VERSION ""

NS_ :

BS_:

BU_: Tritium DriverControls

BO_ 3221225472 VECTOR__INDEPENDENT_SIG_MSG: 0 Vector__XXX
 SG_ Reserved2 : 32|32@1- (1,0) [0|0] "C" Vector__XXX

BO_ 768 IdentificationInfo: 8 Tritium
 SG_ TritiumId : 0|32@1+ (1,0) [0|0] "" Vector__XXX
 SG_ SerialNumber : 32|32@1+ (1,0) [0|0] "" Vector__XXX

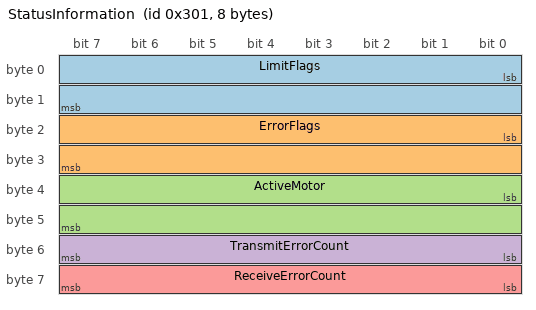
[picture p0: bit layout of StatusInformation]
BO_ 769 StatusInformation: 8 Tritium
 SG_ LimitFlags : 0|16@1+ (1,0) [0|0] "" Vector__XXX
 SG_ ErrorFlags : 16|16@1+ (1,0) [0|0] "" Vector__XXX
 SG_ ActiveMotor : 32|16@1+ (1,0) [0|0] "" Vector__XXX
 SG_ TransmitErrorCount : 48|8@1+ (1,0) [0|0] "" Vector__XXX
 SG_ ReceiveErrorCount : 56|8@1+ (1,0) [0|0] "" Vector__XXX

BO_ 770 BusMeasurement: 8 Tritium
 SG_ BusVoltage : 0|32@1- (1,0) [0|0] "V" Vector__XXX
 SG_ BusCurrent : 32|32@1- (1,0) [0|0] "A" Vector__XXX

BO_ 771 Velocity: 8 Tritium
 SG_ MotorVelocity : 0|32@1- (1,0) [0|0] "rpm" Vector__XXX
 SG_ VehicleVelocity : 32|32@1- (1,0) [0|0] "m/s" Vector__XXX

BO_ 772 PhaseCurrent: 8 Tritium
 SG_ PhaseBCurrent : 0|32@1- (1,0) [0|0] "A_rms" Vector__XXX
 SG_ PhaseCCurrent : 32|32@1- (1,0) [0|0] "A_rms" Vector__XXX

BO_ 773 MotorVoltageVector: 8 Tritium
 SG_ VectVoltImag : 0|32@1- (1,0) [0|0] "V" Vector__XXX
 SG_ VectVoltReal : 32|32@1- (1,0) [0|0] "V" Vector__XXX

BO_ 774 MotorCurrentVector: 8 Tritium
 SG_ VectCurrImag : 0|32@1- (1,0) [0|0] "A" Vector__XXX
 SG_ VectCurrReal : 32|32@1- (1,0) [0|0] "A" Vector__XXX

BO_ 775 MotorBackemfVector: 8 Tritium
 SG_ PeakBackEmfPhaseToNeutral : 0|32@1- (1,0) [0|0] "V" Vector__XXX
 SG_ BackEmfD : 32|32@1- (1,0) [0|0] "V" Vector__XXX

BO_ 776 Rail_15V: 8 Tritium
 SG_ Reserved : 0|32@1- (1,0) [0|0] "V" Vector__XXX
 SG_ FifteenVSupply : 32|32@1- (1,0) [0|0] "V" Vector__XXX

BO_ 777 Rail_3_3VAnd1_9V: 8 Tritium
 SG_ ThreeThreeVSupply : 32|32@1- (1,0) [0|0] "V" Vector__XXX
 SG_ OneNineVSupply : 0|32@1- (1,0) [0|0] "V" Vector__XXX

BO_ 778 Reserved1: 8 Tritium
 SG_ VoltagePercentage : 0|32@1- (1,0) [0|0] "%" Vector__XXX
 SG_ FanSpeed : 32|32@1- (1,0) [0|0] "rpm" Vector__XXX

BO_ 779 SinkMotorTemperature: 8 Tritium
 SG_ MotorTemp : 0|32@1- (1,0) [0|0] "C" Vector__XXX
 SG_ HeatSinkTemp : 32|32@1- (1,0) [0|0] "C" Vector__XXX

BO_ 780 DspBoardTemperature: 8 Tritium
 SG_ DspBoardTemp : 0|32@1- (1,0) [0|0] "C" Vector__XXX
 SG_ Reserved : 32|32@1- (1,0) [0|0] "C" Vector__XXX

BO_ 781 Reserved: 8 Tritium
 SG_ Reserved0 : 0|32@1- (1,0) [0|0] "" Vector__XXX
 SG_ Reserved : 32|32@1- (1,0) [0|0] "C" Vector__XXX

BO_ 782 OdoBusAmphours: 8 Tritium
 SG_ Odometer : 0|32@1- (1,0) [0|0] "m" Vector__XXX
 SG_ DcBusAmpHours : 32|32@1- (1,0) [0|0] "Ah" Vector__XXX

BO_ 791 SlipSpeedMeasurement: 8 Tritium
 SG_ Reserved : 0|32@1- (1,0) [0|0] "C" Vector__XXX
 SG_ SlipSpeed : 32|32@1- (1,0) [0|0] "Hz" Vector__XXX

BO_ 257 SpeedValCurrVal: 8 DriverControls
 SG_ DriverSetSpeed : 0|32@1- (1,0) [0|0] "rpm" Vector__XXX
 SG_ DriverSetCurrent : 32|32@1- (1,0) [0|1] "" Vector__XXX

BO_ 258 Maxbuscurrent: 8 DriverControls
 SG_ MaxBusCurrent : 32|32@1- (1,0) [0|1] "" Vector__XXX
 SG_ Zero : 0|32@1- (1,0) [0|0] "" Vector__XXX

BO_ 1280 DialCurrent: 8 DriverControls
 SG_ DriverSetDialCurrent : 0|32@1- (1,0) [0|1] "" Vector__XXX
 SG_ TotalAcMotorCurrent : 32|32@1- (1,0) [0|1] "" Vector__XXX

CM_ BU_ Tritium "Tritium WaveSculptor22 motor controller: drives the motor and reports its speed, currents, voltages and temperatures. Base address 0x300 (messages 0x300 to 0x317), as in Tests/data/NRT.BIN (iESC 2026 qualifying), where it reports device identifier 0x4003 (WaveSculptor22) and serial number 3315. The 2024 car's controller used base address 0x600. TODO: add the controller firmware version.";
CM_ BU_ DriverControls "Driver controls: send the driver's drive and power commands to the motor controller (base address 0x100), and the current dial setting (0x500).";
CM_ BO_ 3221225472 "Placeholder created by the Vector DBC editor to hold signals that are not in any message. Never sent on the bus.";
CM_ SG_ 3221225472 Reserved2 "Not used.";
CM_ BO_ 768 "Motor controller identification. Sent once a second.";
CM_ SG_ 768 TritiumId "Device identifier, fixed for the model (sent as the characters TRIa on some models).";
CM_ SG_ 768 SerialNumber "Device serial number, allocated at manufacture.";
CM_ BO_ 769 "Motor controller status: which limits are active, errors, and CAN error counts.";
CM_ SG_ 769 ActiveMotor "Index of the motor profile currently in use.";
CM_ SG_ 769 ErrorFlags "Error flags, one bit each (bit 0 hardware over current, bit 1 software over current, bit 2 DC bus over voltage, bit 3 bad motor position hall sequence, bit 4 watchdog caused the last reset, bit 5 config read error, bit 6 15 V rail under voltage lock out). 0 = no errors. TODO: add the remaining bits from the WaveSculptor22 user manual.";
CM_ SG_ 769 LimitFlags "Which limit is currently restricting the controller's output, one bit each (bit 0 bridge PWM, bit 1 motor current, bit 2 velocity, bit 3 bus current, bit 4 bus voltage upper limit, bit 5 bus voltage lower limit, bit 6 heatsink temperature).";
CM_ SG_ 769 TransmitErrorCount "Number of CAN transmit errors counted by the controller.";
CM_ SG_ 769 ReceiveErrorCount "Number of CAN receive errors counted by the controller.";
CM_ BO_ 770 "Battery-side (DC bus) voltage and current at the motor controller.";
CM_ SG_ 770 BusVoltage "DC bus (battery) voltage at the controller.";
CM_ SG_ 770 BusCurrent "Current drawn from the DC bus (battery) by the controller.";
CM_ BO_ 771 "Motor speed and vehicle speed.";
CM_ SG_ 771 MotorVelocity "Motor speed in revolutions per minute.";
CM_ SG_ 771 VehicleVelocity "Vehicle speed in metres per second, calculated by the controller from the motor speed and the wheel size set in its configuration.";
CM_ BO_ 772 "Current in two of the motor's three phases.";
CM_ SG_ 772 PhaseBCurrent "RMS current in motor phase B.";
CM_ SG_ 772 PhaseCCurrent "RMS current in motor phase C.";
CM_ BO_ 773 "Voltage applied to the motor, as a vector (mainly for motor tuning).";
CM_ SG_ 773 VectVoltImag "Imaginary component of the voltage vector applied to the motor.";
CM_ SG_ 773 VectVoltReal "Real component of the voltage vector applied to the motor.";
CM_ BO_ 774 "Current in the motor, as a vector (mainly for motor tuning).";
CM_ SG_ 774 VectCurrImag "Imaginary component of the motor current vector. This is the current that produces torque.";
CM_ SG_ 774 VectCurrReal "Real component of the motor current vector: the field current of the motor.";
CM_ BO_ 775 "Back-EMF (the voltage generated by the spinning motor), as a vector.";
CM_ SG_ 775 PeakBackEmfPhaseToNeutral "Peak phase to neutral back-EMF voltage of the motor.";
CM_ SG_ 775 BackEmfD "By definition always 0 V.";
CM_ BO_ 776 "Voltage of the controller's internal 15 V supply rail.";
CM_ SG_ 776 Reserved "Reserved, not used.";
CM_ SG_ 776 FifteenVSupply "Actual voltage of the internal 15 V supply rail.";
CM_ BO_ 777 "Voltages of the controller's internal 3.3 V and 1.9 V supply rails.";
CM_ SG_ 777 ThreeThreeVSupply "Actual voltage of the internal 3.3 V supply rail.";
CM_ SG_ 777 OneNineVSupply "Actual voltage of the internal 1.9 V (processor) supply rail.";
CM_ BO_ 778 "Cooling fan drive and speed (WaveSculptor20 layout). Marked reserved and not active in the 2023 CAN bus config spreadsheet (CANBusConfig.xlsm, removed in commit 210999e), and not seen in Tests/data/NRT.BIN. TODO: add whether Peri's motor controller sends this message; if not, remove it.";
CM_ SG_ 778 VoltagePercentage "Drive voltage to the cooling fan, in percent. Above 0 % the fan should be spinning.";
CM_ SG_ 778 FanSpeed "Cooling fan speed in revolutions per minute.";
CM_ BO_ 779 "Motor and controller heatsink temperatures.";
CM_ SG_ 779 MotorTemp "Internal temperature of the motor.";
CM_ SG_ 779 HeatSinkTemp "Surface temperature of the controller's heatsink.";
CM_ BO_ 780 "Temperature of the controller's processor board.";
CM_ SG_ 780 DspBoardTemp "Temperature of the controller's processor (DSP) board.";
CM_ SG_ 780 Reserved "Reserved, not used.";
CM_ BO_ 781 "Reserved message: marked reserved and not active in the 2023 CAN bus config spreadsheet (CANBusConfig.xlsm, removed in commit 210999e), but it does appear in Tests/data/NRT.BIN. TODO: add what Peri's motor controller sends in this message (base address + 0x0D), from the WaveSculptor22 user manual.";
CM_ SG_ 781 Reserved0 "Reserved, first half of the message (bits 0 to 31): see the message comment.";
CM_ SG_ 781 Reserved "Reserved, second half of the message (bits 32 to 63). TODO: add its meaning, see the message comment.";
CM_ BO_ 782 "Distance travelled and charge used since the controller was reset.";
CM_ SG_ 782 Odometer "Distance the vehicle has travelled since the controller was reset.";
CM_ SG_ 782 DcBusAmpHours "Charge drawn from the DC bus (battery) since the controller was reset.";
CM_ BO_ 791 "Slip speed (only meaningful with an induction motor).";
CM_ SG_ 791 Reserved "Reserved, not used.";
CM_ SG_ 791 SlipSpeed "Slip speed when driving an induction motor.";
CM_ BO_ 257 "Drive command from the driver controls to the motor controller: target speed and motor current.";
CM_ SG_ 257 DriverSetSpeed "Target motor speed requested by the driver controls, in motor rpm (negative = reverse). Evidence: the 16 BIN captures in (Aug to Nov 2026): about 480 rpm while the motor turns at about 330 rpm, i.e. set above the actual speed so that the current request (DriverSetCurrent) controls the car.";
CM_ SG_ 257 DriverSetCurrent "Motor current requested by the driver controls, as a fraction of the controller's maximum current setting (0 to 1, not 0 to 100). Evidence: the 16 BIN captures in (Aug to Nov 2026): 0 to 0.96.";
CM_ BO_ 258 "Power command from the driver controls: limit on the current drawn from the battery.";
CM_ SG_ 258 MaxBusCurrent "Limit on current drawn from the DC bus (battery), as a fraction of the controller's absolute bus current limit (0 to 1, not 0 to 100). Evidence: the 16 BIN captures in (Aug to Nov 2026): always 1.0.";
CM_ SG_ 258 Zero "Reserved, always 0.";
CM_ BO_ 1280 "Current dial setting from the driver controls (DriverSetCurrent in the ESC-CODE decode sheet). Seen in Tests/data/NRT.BIN.";
CM_ SG_ 1280 DriverSetDialCurrent "Setting of the driver's current dial, as a fraction (nominally 0 to 1). Evidence: the 16 BIN captures in (Aug to Nov 2026): 0 to 1.21. It is the upper limit for TotalAcMotorCurrent.";
CM_ SG_ 1280 TotalAcMotorCurrent "Motor current command sent to the motor controller, as a fraction (0 to 1). Evidence: the 16 BIN captures in (Aug to Nov 2026): 0 to 0.92, never above DriverSetDialCurrent, and in iESC2026_raceday1.BIN equal to the latest DriverSetCurrent in 87 % of messages.";
BA_DEF_ BO_  "GenMsgCycleTime" INT 0 65535;
BA_DEF_DEF_  "GenMsgCycleTime" 0;
BA_ "GenMsgCycleTime" BO_ 768 1000;
BA_ "GenMsgCycleTime" BO_ 769 200;
BA_ "GenMsgCycleTime" BO_ 770 200;
BA_ "GenMsgCycleTime" BO_ 771 200;
BA_ "GenMsgCycleTime" BO_ 772 200;
BA_ "GenMsgCycleTime" BO_ 773 200;
BA_ "GenMsgCycleTime" BO_ 774 200;
BA_ "GenMsgCycleTime" BO_ 775 200;
BA_ "GenMsgCycleTime" BO_ 776 1000;
BA_ "GenMsgCycleTime" BO_ 777 1000;
BA_ "GenMsgCycleTime" BO_ 778 1000;
BA_ "GenMsgCycleTime" BO_ 779 1000;
BA_ "GenMsgCycleTime" BO_ 780 5000;
BA_ "GenMsgCycleTime" BO_ 781 5000;
BA_ "GenMsgCycleTime" BO_ 782 1000;
BA_ "GenMsgCycleTime" BO_ 791 200;
BA_ "GenMsgCycleTime" BO_ 257 100;
BA_ "GenMsgCycleTime" BO_ 258 500;
SIG_VALTYPE_ 770 BusVoltage : 1;
SIG_VALTYPE_ 770 BusCurrent : 1;
SIG_VALTYPE_ 771 MotorVelocity : 1;
SIG_VALTYPE_ 771 VehicleVelocity : 1;
SIG_VALTYPE_ 772 PhaseBCurrent : 1;
SIG_VALTYPE_ 772 PhaseCCurrent : 1;
SIG_VALTYPE_ 773 VectVoltImag : 1;
SIG_VALTYPE_ 773 VectVoltReal : 1;
SIG_VALTYPE_ 774 VectCurrImag : 1;
SIG_VALTYPE_ 774 VectCurrReal : 1;
SIG_VALTYPE_ 775 PeakBackEmfPhaseToNeutral : 1;
SIG_VALTYPE_ 775 BackEmfD : 1;
SIG_VALTYPE_ 776 Reserved : 1;
SIG_VALTYPE_ 776 FifteenVSupply : 1;
SIG_VALTYPE_ 777 ThreeThreeVSupply : 1;
SIG_VALTYPE_ 777 OneNineVSupply : 1;
SIG_VALTYPE_ 778 VoltagePercentage : 1;
SIG_VALTYPE_ 778 FanSpeed : 1;
SIG_VALTYPE_ 779 MotorTemp : 1;
SIG_VALTYPE_ 779 HeatSinkTemp : 1;
SIG_VALTYPE_ 780 DspBoardTemp : 1;
SIG_VALTYPE_ 780 Reserved : 1;
SIG_VALTYPE_ 781 Reserved0 : 1;
SIG_VALTYPE_ 781 Reserved : 1;
SIG_VALTYPE_ 782 Odometer : 1;
SIG_VALTYPE_ 782 DcBusAmpHours : 1;
SIG_VALTYPE_ 791 Reserved : 1;
SIG_VALTYPE_ 791 SlipSpeed : 1;
SIG_VALTYPE_ 257 DriverSetSpeed : 1;
SIG_VALTYPE_ 257 DriverSetCurrent : 1;
SIG_VALTYPE_ 258 MaxBusCurrent : 1;
SIG_VALTYPE_ 258 Zero : 1;
SIG_VALTYPE_ 1280 DriverSetDialCurrent : 1;
SIG_VALTYPE_ 1280 TotalAcMotorCurrent : 1;
